AUTOSAR XML (schema 4-2-2)
package /ASW_COM_Package
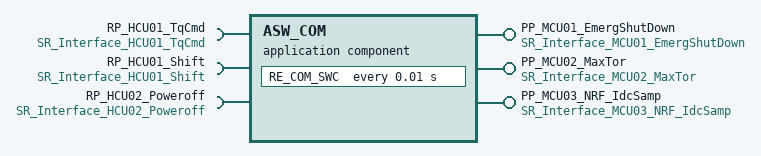
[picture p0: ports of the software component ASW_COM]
  application sw component type ASW_COM
    provide port PP_MCU01_EmergShutDown: nonqueued-sender-com-spec{data-element=DE_MCU01_EmergShutDown, init-value=0}, provided-interface=SR_Interface_MCU01_EmergShutDown
    provide port PP_MCU02_MaxTor: nonqueued-sender-com-spec{data-element=DE_MCU02_MaxTor, init-value=0}, provided-interface=SR_Interface_MCU02_MaxTor
    provide port PP_MCU03_NRF_IdcSamp: nonqueued-sender-com-spec{data-element=DE_MCU03_NRF_IdcSamp, init-value=0}, provided-interface=SR_Interface_MCU03_NRF_IdcSamp
    require port RP_HCU01_TqCmd: nonqueued-receiver-com-spec{data-element=DE_HCU01_TqCmd, init-value=0}, required-interface=SR_Interface_HCU01_TqCmd
    require port RP_HCU01_Shift: nonqueued-receiver-com-spec{data-element=DE_HCU01_Shift, init-value=0}, required-interface=SR_Interface_HCU01_Shift
    require port RP_HCU02_Poweroff: nonqueued-receiver-com-spec{data-element=DE_HCU02_Poweroff, alive-timeout=0.3, init-value=0}, required-interface=SR_Interface_HCU02_Poweroff
    behavior IB_ASW_COM
      timing event TE_RE_COM_SWC_10ms: start-on-event=RE_COM_SWC, period=0.01
      runnable RE_COM_SWC
        data-read-access:
          access VA_READ_HCU01_TqCmd: accessed-variable=RP_HCU01_TqCmd.DE_HCU01_TqCmd
          access VA_READ_HCU01_Shift: accessed-variable=RP_HCU01_Shift.DE_HCU01_Shift
          access VA_READ_HCU02_Poweroff: accessed-variable=RP_HCU02_Poweroff.DE_HCU02_Poweroff
        data-write-access:
          access VA_WRITE_MCU01_EmergShutDown: accessed-variable=PP_MCU01_EmergShutDown.DE_MCU01_EmergShutDown
          access VA_WRITE_MCU02_MaxTor: accessed-variable=PP_MCU02_MaxTor.DE_MCU02_MaxTor
          access VA_WRITE_MCU03_NRF_IdcSamp: accessed-variable=PP_MCU03_NRF_IdcSamp.DE_MCU03_NRF_IdcSamp
package /COM_Interface
  6 x sender receiver interface:
    SR_Interface_HCU01_Shift
      data DE_HCU01_Shift: type=dt_uint8
    SR_Interface_HCU01_TqCmd
      data DE_HCU01_TqCmd: type=dt_float32
    SR_Interface_HCU02_Poweroff
      data DE_HCU02_Poweroff: type=dt_bool
    SR_Interface_MCU01_EmergShutDown
      data DE_MCU01_EmergShutDown: type=dt_bool
    SR_Interface_MCU02_MaxTor
      data DE_MCU02_MaxTor: type=dt_float32
    SR_Interface_MCU03_NRF_IdcSamp
      data DE_MCU03_NRF_IdcSamp: type=dt_float32
package /DataTypes
  app type dt_bool: category=VALUE
  app type dt_float32: category=VALUE
  app type dt_uint8: category=VALUE
